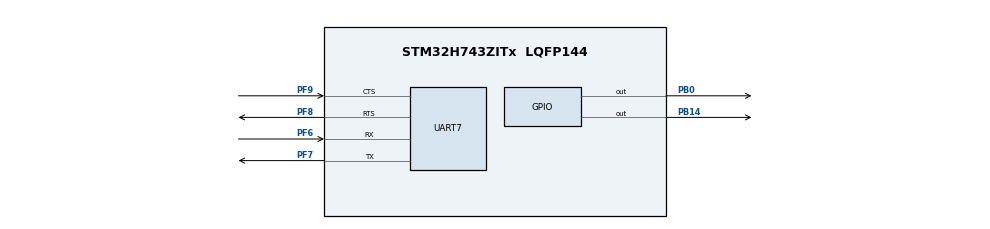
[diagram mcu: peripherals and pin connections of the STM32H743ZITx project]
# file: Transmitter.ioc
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CORTEX_M7.default_mode_Activation=1
Mcu.Family=STM32H7
Mcu.Name=STM32H743ZITx
Mcu.Package=LQFP144
NVIC.PriorityGroup=NVIC_PRIORITYGROUP_4
PA13\ (JTMS/SWDIO).GPIO_Label=JTMS
PA13\ (JTMS/SWDIO).Signal=DEBUG_JTMS-SWDIO
PA14\ (JTCK/SWCLK).GPIO_Label=JTCK
PA14\ (JTCK/SWCLK).Signal=DEBUG_JTCK-SWCLK
PB0.Signal=GPIO_Output
PB14.Signal=GPIO_Output
PC14-OSC32_IN\ (OSC32_IN).Signal=RCC_OSC32_IN
PC15-OSC32_OUT\ (OSC32_OUT).Signal=RCC_OSC32_OUT
PD8.GPIO_Label=STLINK_RX
PD8.Signal=USART3_TX
PD9.GPIO_Label=STLINK_TX
PD9.Signal=USART3_RX
PF6.Mode=Asynchronous
PF6.Signal=UART7_RX
PF7.Mode=Asynchronous
PF7.Signal=UART7_TX
PF8.Mode=CTS_RTS
PF8.Signal=UART7_RTS
PF9.Mode=CTS_RTS
PF9.Signal=UART7_CTS
PH0-OSC_IN\ (PH0).Signal=RCC_OSC_IN
PH1-OSC_OUT\ (PH1).Signal=RCC_OSC_OUT
ProjectManager.HeapSize=0x200
ProjectManager.StackSize=0x400
ProjectManager.TargetToolchain=STM32CubeIDE
RCC.ADCFreq_Value=129000000
RCC.APB1Freq_Value=32000000
RCC.APB2Freq_Value=64000000
RCC.APB3Freq_Value=64000000
RCC.APB4Freq_Value=64000000
RCC.CortexFreq_Value=64000000
RCC.D2PPRE1=RCC_APB1_DIV2
RCC.HCLKFreq_Value=64000000
RCC.SYSCLKFreq_VALUE=64000000
RCC.USBFreq_Value=129000000
VP_MEMORYMAP_VS_MEMORYMAP.Mode=CurAppReg
board=NUCLEO-H743ZI2

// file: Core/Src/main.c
/* USER CODE BEGIN Header */
/**
  ******************************************************************************
  * @file           : main.c
  * @brief          : Main program body
  ******************************************************************************
  * @attention
  *
  * Copyright (c) 2026 STMicroelectronics.
  * All rights reserved.
  *
  * This software is licensed under terms that can be found in the LICENSE file
  * in the root directory of this software component.
  * If no LICENSE file comes with this software, it is provided AS-IS.
  *
  ******************************************************************************
  */
/* USER CODE END Header */
#include "main.h"

UART_HandleTypeDef huart7;

void SystemClock_Config(void);
static void MPU_Config(void);
static void MX_GPIO_Init(void);
static void MX_UART7_Init(void);

int main(void)
{

  /* USER CODE BEGIN 1 */
	const uint8_t command_example[] = {3, 6, 36};
	HAL_StatusTypeDef transmission_result;
  /* USER CODE END 1 */

  /* MPU Configuration--------------------------------------------------------*/
  MPU_Config();

  /* MCU Configuration--------------------------------------------------------*/

  /* Reset of all peripherals, Initializes the Flash interface and the Systick. */
  HAL_Init();

  /* Configure the system clock */
  SystemClock_Config();

  /* Initialize all configured peripherals */
  MX_GPIO_Init();
  MX_UART7_Init();

  /* Infinite loop */
  while (1)
  {

    /* USER CODE BEGIN 3 */
	  transmission_result = HAL_UART_Transmit(&huart7, command_example,
	  			  sizeof(command_example) / sizeof(command_example[0]), 1000);

	  if (transmission_result == HAL_OK){
		  HAL_GPIO_TogglePin(GPIOB, GPIO_PIN_0);	// Green LED.
		  HAL_Delay(1000);
		  HAL_GPIO_TogglePin(GPIOB, GPIO_PIN_0);
	  }
	  else{
		  HAL_GPIO_TogglePin(GPIOB, GPIO_PIN_14);	// Red LED.
		  HAL_Delay(1000);
		  HAL_GPIO_TogglePin(GPIOB, GPIO_PIN_14);
	  }

	  HAL_Delay(10000);
  }
  /* USER CODE END 3 */
}

void SystemClock_Config(void)
{
  RCC_OscInitTypeDef RCC_OscInitStruct = {0};
  RCC_ClkInitTypeDef RCC_ClkInitStruct = {0};

  /** Supply configuration update enable
  */
  HAL_PWREx_ConfigSupply(PWR_LDO_SUPPLY);

  /** Configure the main internal regulator output voltage
  */
  __HAL_PWR_VOLTAGESCALING_CONFIG(PWR_REGULATOR_VOLTAGE_SCALE3);

  while(!__HAL_PWR_GET_FLAG(PWR_FLAG_VOSRDY)) {}

  /** Initializes the RCC Oscillators according to the specified parameters
  * in the RCC_OscInitTypeDef structure.
  */
  RCC_OscInitStruct.OscillatorType = RCC_OSCILLATORTYPE_HSI;
  RCC_OscInitStruct.HSIState = RCC_HSI_DIV1;
  RCC_OscInitStruct.HSICalibrationValue = RCC_HSICALIBRATION_DEFAULT;
  RCC_OscInitStruct.PLL.PLLState = RCC_PLL_NONE;
  if (HAL_RCC_OscConfig(&RCC_OscInitStruct) != HAL_OK)
  {
    Error_Handler();
  }

  /** Initializes the CPU, AHB and APB buses clocks
  */
  RCC_ClkInitStruct.ClockType = RCC_CLOCKTYPE_HCLK|RCC_CLOCKTYPE_SYSCLK
                              |RCC_CLOCKTYPE_PCLK1|RCC_CLOCKTYPE_PCLK2
                              |RCC_CLOCKTYPE_D3PCLK1|RCC_CLOCKTYPE_D1PCLK1;
  RCC_ClkInitStruct.SYSCLKSource = RCC_SYSCLKSOURCE_HSI;
  RCC_ClkInitStruct.SYSCLKDivider = RCC_SYSCLK_DIV1;
  RCC_ClkInitStruct.AHBCLKDivider = RCC_HCLK_DIV1;
  RCC_ClkInitStruct.APB3CLKDivider = RCC_APB3_DIV1;
  RCC_ClkInitStruct.APB1CLKDivider = RCC_APB1_DIV2;
  RCC_ClkInitStruct.APB2CLKDivider = RCC_APB2_DIV1;
  RCC_ClkInitStruct.APB4CLKDivider = RCC_APB4_DIV1;

  if (HAL_RCC_ClockConfig(&RCC_ClkInitStruct, FLASH_LATENCY_1) != HAL_OK)
  {
    Error_Handler();
  }
}

static void MX_UART7_Init(void)
{

  huart7.Instance = UART7;
  huart7.Init.BaudRate = 115200;
  huart7.Init.WordLength = UART_WORDLENGTH_8B;
  huart7.Init.StopBits = UART_STOPBITS_1;
  huart7.Init.Parity = UART_PARITY_NONE;
  huart7.Init.Mode = UART_MODE_TX_RX;
  huart7.Init.HwFlowCtl = UART_HWCONTROL_RTS_CTS;
  huart7.Init.OverSampling = UART_OVERSAMPLING_16;
  huart7.Init.OneBitSampling = UART_ONE_BIT_SAMPLE_DISABLE;
  huart7.Init.ClockPrescaler = UART_PRESCALER_DIV1;
  huart7.AdvancedInit.AdvFeatureInit = UART_ADVFEATURE_NO_INIT;
  if (HAL_UART_Init(&huart7) != HAL_OK)
  {
    Error_Handler();
  }
  if (HAL_UARTEx_SetTxFifoThreshold(&huart7, UART_TXFIFO_THRESHOLD_1_8) != HAL_OK)
  {
    Error_Handler();
  }
  if (HAL_UARTEx_SetRxFifoThreshold(&huart7, UART_RXFIFO_THRESHOLD_1_8) != HAL_OK)
  {
    Error_Handler();
  }
  if (HAL_UARTEx_DisableFifoMode(&huart7) != HAL_OK)
  {
    Error_Handler();
  }

}

static void MX_GPIO_Init(void)
{
  GPIO_InitTypeDef GPIO_InitStruct = {0};

  /* GPIO Ports Clock Enable */
  __HAL_RCC_GPIOC_CLK_ENABLE();
  __HAL_RCC_GPIOF_CLK_ENABLE();
  __HAL_RCC_GPIOH_CLK_ENABLE();
  __HAL_RCC_GPIOB_CLK_ENABLE();
  __HAL_RCC_GPIOD_CLK_ENABLE();
  __HAL_RCC_GPIOA_CLK_ENABLE();

  /*Configure GPIO pin Output Level */
  HAL_GPIO_WritePin(GPIOB, GPIO_PIN_0|GPIO_PIN_14, GPIO_PIN_RESET);

  /*Configure GPIO pins : PB0 PB14 */
  GPIO_InitStruct.Pin = GPIO_PIN_0|GPIO_PIN_14;
  GPIO_InitStruct.Mode = GPIO_MODE_OUTPUT_PP;
  GPIO_InitStruct.Pull = GPIO_NOPULL;
  GPIO_InitStruct.Speed = GPIO_SPEED_FREQ_LOW;
  HAL_GPIO_Init(GPIOB, &GPIO_InitStruct);

  /*Configure GPIO pins : STLINK_RX_Pin STLINK_TX_Pin */
  GPIO_InitStruct.Pin = STLINK_RX_Pin|STLINK_TX_Pin;
  GPIO_InitStruct.Mode = GPIO_MODE_AF_PP;
  GPIO_InitStruct.Pull = GPIO_NOPULL;
  GPIO_InitStruct.Speed = GPIO_SPEED_FREQ_LOW;
  GPIO_InitStruct.Alternate = GPIO_AF7_USART3;
  HAL_GPIO_Init(GPIOD, &GPIO_InitStruct);

}

 /* MPU Configuration */

void MPU_Config(void)
{
  MPU_Region_InitTypeDef MPU_InitStruct = {0};

  /* Disables the MPU */
  HAL_MPU_Disable();

  /** Initializes and configures the Region and the memory to be protected
  */
  MPU_InitStruct.Enable = MPU_REGION_ENABLE;
  MPU_InitStruct.Number = MPU_REGION_NUMBER0;
  MPU_InitStruct.BaseAddress = 0x0;
  MPU_InitStruct.Size = MPU_REGION_SIZE_4GB;
  MPU_InitStruct.SubRegionDisable = 0x87;
  MPU_InitStruct.TypeExtField = MPU_TEX_LEVEL0;
  MPU_InitStruct.AccessPermission = MPU_REGION_NO_ACCESS;
  MPU_InitStruct.DisableExec = MPU_INSTRUCTION_ACCESS_DISABLE;
  MPU_InitStruct.IsShareable = MPU_ACCESS_SHAREABLE;
  MPU_InitStruct.IsCacheable = MPU_ACCESS_NOT_CACHEABLE;
  MPU_InitStruct.IsBufferable = MPU_ACCESS_NOT_BUFFERABLE;

  HAL_MPU_ConfigRegion(&MPU_InitStruct);
  /* Enables the MPU */
  HAL_MPU_Enable(MPU_PRIVILEGED_DEFAULT);

}

void Error_Handler(void)
{
  __disable_irq();
  while (1)
  {
  }
}
